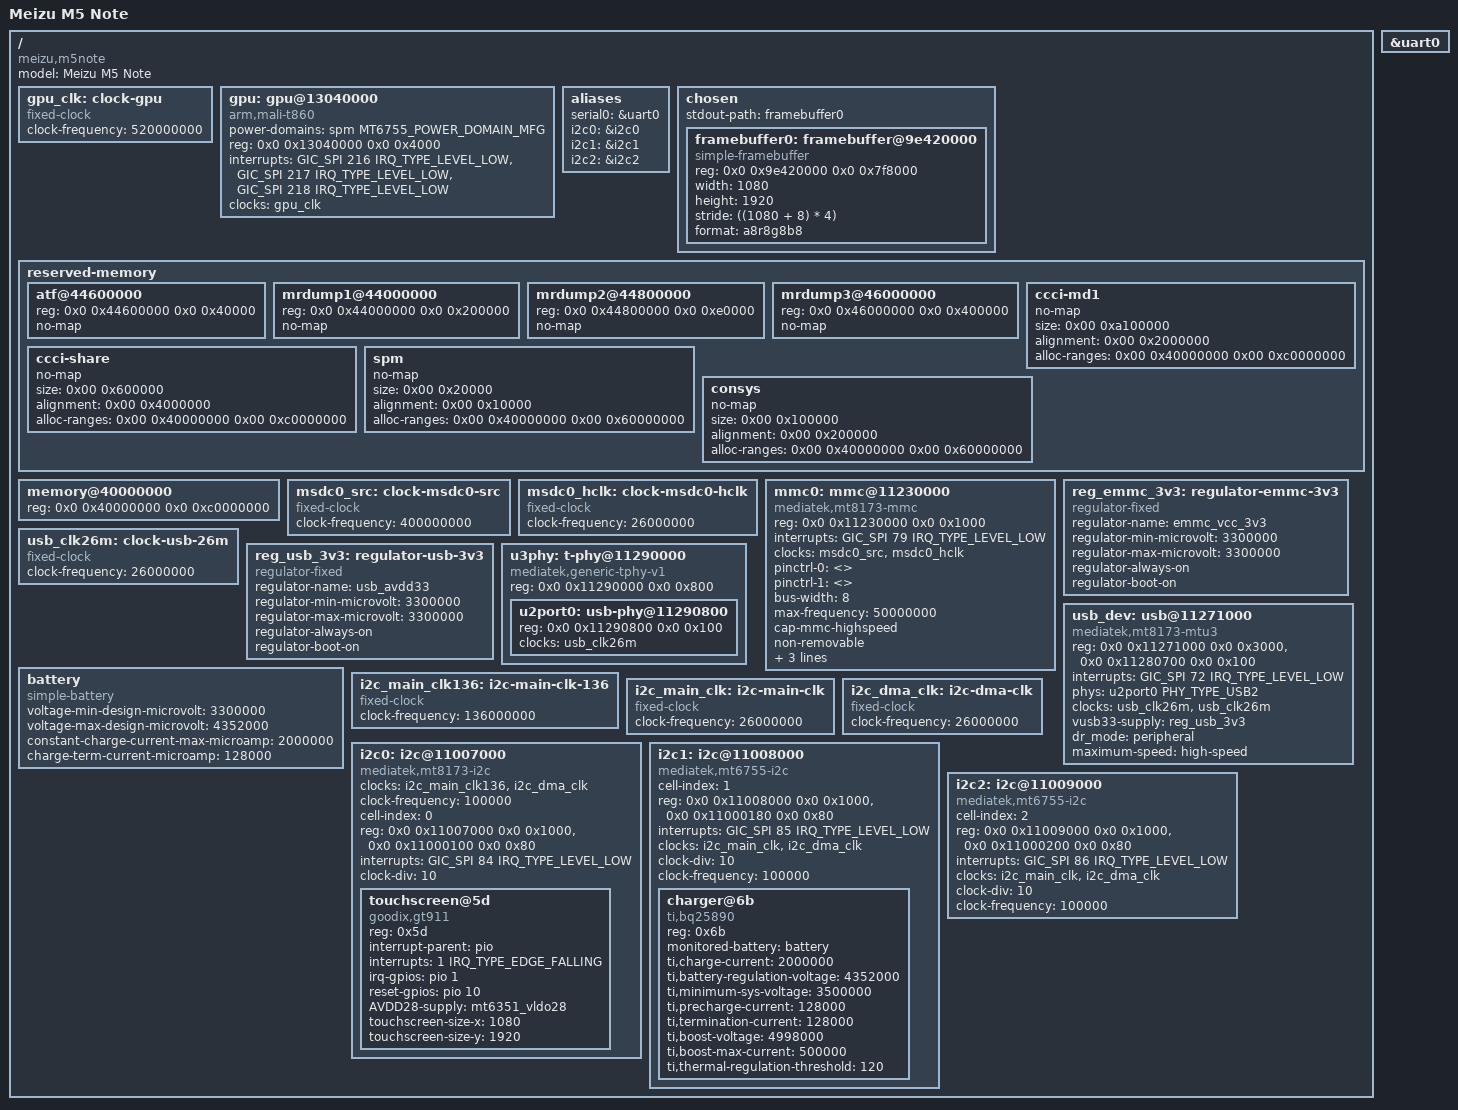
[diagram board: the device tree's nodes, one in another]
// SPDX-License-Identifier: GPL-2.0
/dts-v1/;

#include <dt-bindings/gpio/gpio.h>
#include <dt-bindings/power/mt6755-power.h>
#include <dt-bindings/interrupt-controller/arm-gic.h>
#include <dt-bindings/interrupt-controller/irq.h>
#include <dt-bindings/phy/phy.h>
#include "mt6755.dtsi"


/ {
   	gpu_clk: clock-gpu {
   		compatible = "fixed-clock";
   		#clock-cells = <0>;
   		clock-frequency = <520000000>;
   	};

   	gpu: gpu@13040000 {
		power-domains = <&spm MT6755_POWER_DOMAIN_MFG>;
   		compatible = "arm,mali-t860";
   		reg = <0x0 0x13040000 0x0 0x4000>;
   		interrupts = <GIC_SPI 216 IRQ_TYPE_LEVEL_LOW>,
   			     <GIC_SPI 217 IRQ_TYPE_LEVEL_LOW>,
   			     <GIC_SPI 218 IRQ_TYPE_LEVEL_LOW>;
   		interrupt-names = "gpu", "mmu", "job";
   		clocks = <&gpu_clk>;
   		status = "okay";
   	};
   };


/ {
	/* LK принудительно заменяет /model */
	model = "Meizu M5 Note";
	compatible = "meizu,m5note", "mediatek,mt6755";

	aliases {
		serial0 = &uart0;
	};

	chosen {
		stdout-path = "framebuffer0";

		/* значения сняты с живого Android: fb_base 0x7e800000, stride 4352 */
		framebuffer0: framebuffer@9e420000 {
			compatible = "simple-framebuffer";
			reg = <0x0 0x9e420000 0x0 0x7f8000>;
			width = <1080>;
			height = <1920>;
			stride = <((1080 + 8) * 4)>;
			format = "a8r8g8b8";
		};
	};

	/* /reserved-memory должен существовать, иначе LK недоволен */
	reserved-memory {
		#address-cells = <2>;
		#size-cells = <2>;
		ranges;

		/* то же, что LK резервирует в cmdline (mrdump) и в стоковом DTB (ATF) */
		atf@44600000 {
			reg = <0x0 0x44600000 0x0 0x40000>;
			no-map;
		};
		mrdump1@44000000 {
			reg = <0x0 0x44000000 0x0 0x200000>;
			no-map;
		};
		mrdump2@44800000 {
			reg = <0x0 0x44800000 0x0 0xe0000>;
			no-map;
		};
		mrdump3@46000000 {
			reg = <0x0 0x46000000 0x0 0x400000>;
			no-map;
		};

		ccci-md1 {
			no-map;
			size = <0x00 0xa100000>;
			alignment = <0x00 0x2000000>;
			alloc-ranges = <0x00 0x40000000 0x00 0xc0000000>;
		};
		ccci-share {
			no-map;
			size = <0x00 0x600000>;
			alignment = <0x00 0x4000000>;
			alloc-ranges = <0x00 0x40000000 0x00 0xc0000000>;
		};
		spm {
			no-map;
			size = <0x00 0x20000>;
			alignment = <0x00 0x10000>;
			alloc-ranges = <0x00 0x40000000 0x00 0x60000000>;
		};
		consys {
			no-map;
			size = <0x00 0x100000>;
			alignment = <0x00 0x200000>;
			alloc-ranges = <0x00 0x40000000 0x00 0x60000000>;
		};
	};

	/* заглушка: LK сам подставляет реальные диапазоны памяти */
	memory@40000000 {
		device_type = "memory";
		reg = <0x0 0x40000000 0x0 0xc0000000>;
	};
};

&uart0 {
	status = "okay";
};

/* eMMC (msdc0): LK уже инициализировал контроллер, такты берём фиксированные */
/ {
	msdc0_src: clock-msdc0-src {
		compatible = "fixed-clock";
		#clock-cells = <0>;
		clock-frequency = <400000000>;
	};

	msdc0_hclk: clock-msdc0-hclk {
		compatible = "fixed-clock";
		#clock-cells = <0>;
		clock-frequency = <26000000>;
	};

	mmc0: mmc@11230000 {
		compatible = "mediatek,mt8173-mmc";
		reg = <0x0 0x11230000 0x0 0x1000>;
		interrupts = <GIC_SPI 79 IRQ_TYPE_LEVEL_LOW>;
		clocks = <&msdc0_src>, <&msdc0_hclk>;
		clock-names = "source", "hclk";
		pinctrl-names = "default", "state_uhs";
		pinctrl-0 = <>;
		pinctrl-1 = <>;
		bus-width = <8>;
		max-frequency = <50000000>;
		cap-mmc-highspeed;
		non-removable;
		no-sd;
		no-sdio;
		status = "okay";
	};
};


/* питание eMMC: LK его уже включил, ядру только сообщаем напряжение */
/ {
	reg_emmc_3v3: regulator-emmc-3v3 {
		compatible = "regulator-fixed";
		regulator-name = "emmc_vcc_3v3";
		regulator-min-microvolt = <3300000>;
		regulator-max-microvolt = <3300000>;
		regulator-always-on;
		regulator-boot-on;
	};
};

&mmc0 {
	vmmc-supply = <&reg_emmc_3v3>;
};

/* USB (SSUSB/mtu3) только в режиме устройства; такты и питание: LK уже включил */
/ {
	usb_clk26m: clock-usb-26m {
		compatible = "fixed-clock";
		#clock-cells = <0>;
		clock-frequency = <26000000>;
	};

	reg_usb_3v3: regulator-usb-3v3 {
		compatible = "regulator-fixed";
		regulator-name = "usb_avdd33";
		regulator-min-microvolt = <3300000>;
		regulator-max-microvolt = <3300000>;
		regulator-always-on;
		regulator-boot-on;
	};

	u3phy: t-phy@11290000 {
		compatible = "mediatek,generic-tphy-v1";
		reg = <0x0 0x11290000 0x0 0x800>;
		#address-cells = <2>;
		#size-cells = <2>;
		ranges;
		status = "okay";

		u2port0: usb-phy@11290800 {
			reg = <0x0 0x11290800 0x0 0x100>;
			clocks = <&usb_clk26m>;
			clock-names = "ref";
			#phy-cells = <1>;
			status = "okay";
		};
	};

	usb_dev: usb@11271000 {
		compatible = "mediatek,mt8173-mtu3";
		reg = <0x0 0x11271000 0x0 0x3000>, <0x0 0x11280700 0x0 0x100>;
		reg-names = "mac", "ippc";
		interrupts = <GIC_SPI 72 IRQ_TYPE_LEVEL_LOW>;
		phys = <&u2port0 PHY_TYPE_USB2>;
		clocks = <&usb_clk26m>, <&usb_clk26m>;
		clock-names = "sys_ck", "ref_ck";
		vusb33-supply = <&reg_usb_3v3>;
		dr_mode = "peripheral";
		maximum-speed = "high-speed";
		status = "okay";
	};

};

/ {
	/* Узел батареи — ОБЯЗАТЕЛЬНО с нужными свойствами */
	battery: battery {
		compatible = "simple-battery";

		/* Напряжение батареи */
		voltage-min-design-microvolt = <3300000>;  /* 3.3V минимальное */
		voltage-max-design-microvolt = <4352000>;  /* 4.352V максимальное */

		/* Ток заряда */
		constant-charge-current-max-microamp = <2000000>;   /* 2000mA */
		charge-term-current-microamp = <128000>;            /* 128mA */

		/* Ёмкость (опционально, но желательно) */
		/*charge-full-design-microamp-hours = <3000000>;      /* 3000mAh */
	};
};


/ {
};

/ {
	i2c_main_clk136: i2c-main-clk-136 {
		compatible = "fixed-clock";
		#clock-cells = <0>;
		clock-frequency = <136000000>;
	};
};


/* I2C1: the charger (bq25890 at 0x6b) and sensors live here. LK has set the clocks up */
/ {
	aliases {
		i2c0 = &i2c0;
		i2c1 = &i2c1;
		i2c2 = &i2c2;
	};



	/* Фиктивные часы */
	i2c_main_clk: i2c-main-clk {
		compatible = "fixed-clock";
		#clock-cells = <0>;
		clock-frequency = <26000000>;
	};

	i2c_dma_clk: i2c-dma-clk {
		compatible = "fixed-clock";
		#clock-cells = <0>;
		clock-frequency = <26000000>;
	};

	/* I2C0 */
	i2c0: i2c@11007000 {

		compatible = "mediatek,mt8173-i2c";
		clocks = <&i2c_main_clk136>, <&i2c_dma_clk>;
		clock-frequency = <100000>;

		//compatible = "mediatek,mt6755-i2c";
		cell-index = <0>;
		reg = <0x0 0x11007000 0x0 0x1000>,
		      <0x0 0x11000100 0x0 0x80>;
		interrupts = <GIC_SPI 84 IRQ_TYPE_LEVEL_LOW>;
		//clocks = <&i2c_main_clk>, <&i2c_dma_clk>;
		clock-names = "main", "dma";
		clock-div = <10>;
		//clock-frequency = <400000>;
		#address-cells = <1>;
		#size-cells = <0>;
		status = "okay";

		/* variant A: Goodix (stock ID string GT915L,BIEL) */
		touchscreen@5d {
	compatible = "goodix,gt911";
	reg = <0x5d>;
	interrupt-parent = <&pio>;
	interrupts = <1 IRQ_TYPE_EDGE_FALLING>;
	irq-gpios = <&pio 1 GPIO_ACTIVE_HIGH>;
	reset-gpios = <&pio 10 GPIO_ACTIVE_HIGH>;
	AVDD28-supply = <&mt6351_vldo28>;
	touchscreen-size-x = <1080>;
	touchscreen-size-y = <1920>;
};


	};

	/* I2C1 — здесь bq25890 */
	i2c1: i2c@11008000 {
		compatible = "mediatek,mt6755-i2c";
		cell-index = <1>;
		reg = <0x0 0x11008000 0x0 0x1000>,
		      <0x0 0x11000180 0x0 0x80>;
		interrupts = <GIC_SPI 85 IRQ_TYPE_LEVEL_LOW>;
		clocks = <&i2c_main_clk>, <&i2c_dma_clk>;
		clock-names = "main", "dma";
		clock-div = <10>;
		clock-frequency = <100000>;
		#address-cells = <1>;
		#size-cells = <0>;
		status = "okay";
		charger@6b {
		compatible = "ti,bq25890";
		reg = <0x6b>;

		/* Ссылка на узел батареи */
		monitored-battery = <&battery>;

		/* ОБЯЗАТЕЛЬНЫЕ свойства для mainline драйвера */
		ti,charge-current = <2000000>;              /* 2000mA ток заряда */
		ti,battery-regulation-voltage = <4352000>;  /* 4.352V напряжение заряда */
		ti,minimum-sys-voltage = <3500000>;         /* 3.5V минимальное системное */
		ti,precharge-current = <128000>;            /* 128mA предварительный заряд */
		ti,termination-current = <128000>;          /* 128mA ток завершения */

		/* НОВЫЕ обязательные свойства для OTG boost */
		ti,boost-voltage = <4998000>;               /* 4.998V напряжение boost */
		ti,boost-max-current = <500000>;            /* 500mA максимальный ток boost */

		/* Опциональные свойства */
		ti,thermal-regulation-threshold = <120>;    /* 120°C порог терморегуляции */

		/* Если нет OTG (только microUSB на вход), можно отключить boost */
		/* ti,use-ilim-pin; */  /* Раскомментируй, если используешь ILIM pin */
	};

	};

	/* I2C2 */
	i2c2: i2c@11009000 {
		compatible = "mediatek,mt6755-i2c";
		cell-index = <2>;
		reg = <0x0 0x11009000 0x0 0x1000>,
		      <0x0 0x11000200 0x0 0x80>;
		interrupts = <GIC_SPI 86 IRQ_TYPE_LEVEL_LOW>;
		clocks = <&i2c_main_clk>, <&i2c_dma_clk>;
		clock-names = "main", "dma";
		clock-div = <10>;
		clock-frequency = <100000>;
		#address-cells = <1>;
		#size-cells = <0>;
		status = "okay";
	};
};


